# Cortex-M35P register map
Vendor: ARM Ltd.
CPU: Cortex-M35P r0p0, little endian, MPU, FPU, double-precision FPU, VTOR, vendor SysTick, 8 interrupt priority bits
Registers are 32-bit, read-write, no defined reset value unless marked. A register's access mark holds for its fields unless they carry their own. Offsets are from the block's base; [hi:lo] are bit positions; {n}, {i} and the like mark numbered series.

## CM — Cache Maintenance Operations
Base ?
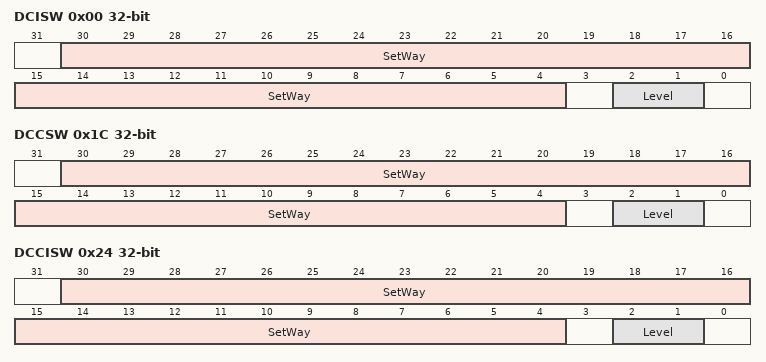
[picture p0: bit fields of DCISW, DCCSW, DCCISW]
0x00 DCISW wo
  [30:4] SetWay — Cache set/way
  [2:1] Level — Cache level
0x00 ICIALLU wo
  [30:0] Ignored — The value written to this field is ignored
0x08 ICIMVAU wo
  [30:0] ADDRESS
0x0C DCIMVAC wo
  [30:0] ADDRESS
0x14 DCCMVAU wo
  [30:0] ADDRESS
0x18 DCCMVAC wo
  [30:0] ADDRESS
0x1C DCCSW wo
  [30:4] SetWay — Cache set/way
  [2:1] Level — Cache level
0x20 DCCIMVAC wo
  [30:0] ADDRESS
0x24 DCCISW wo
  [30:4] SetWay — Cache set/way
  [2:1] Level — Cache level
0x28 BPIALL wo
  [30:0] Ignored

## ICB — Interrupt Control Registers
Base ?
0x00 ICTR ro
  [2:0] INTLINESNUM — Interrupt line set number
0x04 ACTLR
0x08 CPPWR
  [23] SUS11 — State UNKNOWN Secure only 11
  [22] SU11 — State UNKNOWN 11
  [21] SUS10 — State UNKNOWN Secure only 10
  [20] SU10 — State UNKNOWN 10
  [n] SUS{n} (n=0..7) — State UNKNOWN Secure only {n}
  [n] SU{n} (n=0..7) — State UNKNOWN {n}

## DCB — Debug Registers
Base ?
0x00 DHCSR
  [26] S_RESTART_ST — Restart sticky status
  [25] S_RESET_ST — Reset sticky status
  [24] S_RETIRE_ST — Retire sticky status
  [20] S_SDE — Secure debug enabled
  [19] S_LOCKUP — Lockup status
  [18] S_SLEEP — Sleeping status
  [17] S_HALT — Halted status
  [30:16] DBGKEY — Debug key
  [16] S_REGRDY — Register ready status
  [5] C_SNAPSTALL — Snap stall control
  [3] C_MASKINTS — Mask interrupts control
  [2] C_STEP — Step control
  [1] C_HALT — Halt control
  [0] C_DEBUGEN — Debug enable control
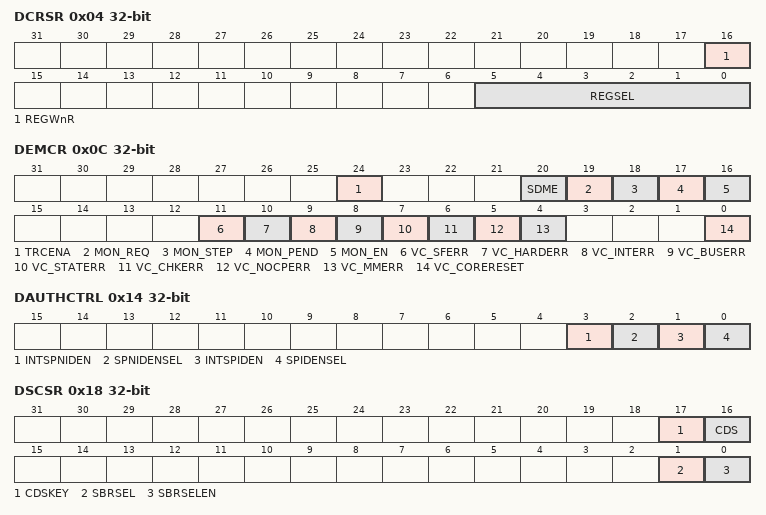
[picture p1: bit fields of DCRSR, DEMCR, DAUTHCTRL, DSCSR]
0x04 DCRSR wo
  [16] REGWnR — Register write/not-read
  [5:0] REGSEL — Register selector
0x08 DCRDR
  [30:0] DBGTMP — Data temporary buffer
0x0C DEMCR ro
  [24] TRCENA — Trace enable
  [20] SDME — Secure DebugMonitor enable
  [19] MON_REQ — Monitor request
  [18] MON_STEP — Monitor step
  [17] MON_PEND — Monitor pend
  [16] MON_EN — Monitor enable
  [11] VC_SFERR — Vector Catch SecureFault
  [10] VC_HARDERR — Vector Catch HardFault errors
  [9] VC_INTERR — Vector Catch interrupt errors
  [8] VC_BUSERR — Vector Catch BusFault errors
  [7] VC_STATERR — Vector Catch state errors
  [6] VC_CHKERR — Vector Catch check errors
  [5] VC_NOCPERR — Vector Catch NOCP errors
  [4] VC_MMERR — Vector Catch MemManage errors
  [0] VC_CORERESET — Vector Catch core reset
0x14 DAUTHCTRL
  [3] INTSPNIDEN — Internal Secure non-invasive debug enable
  [2] SPNIDENSEL — Secure non-invasive debug enable select
  [1] INTSPIDEN — Internal Secure invasive debug enable
  [0] SPIDENSEL — Secure invasive debug enable select
0x18 DSCSR ro
  [17] CDSKEY — CDS write-enable key
  [16] CDS — Current domain Secure
  [1] SBRSEL — Secure Banked register select
  [0] SBRSELEN — Secure Banked register select enable

## DIB — Identification Registers
Base ?
0x00 DLAR wo
  [30:0] KEY — Lock Access control
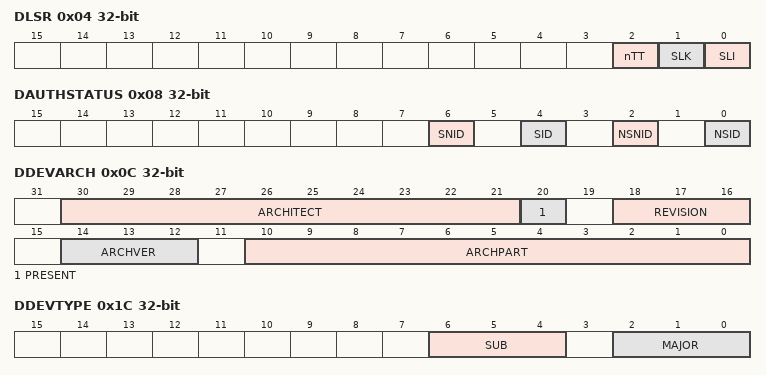
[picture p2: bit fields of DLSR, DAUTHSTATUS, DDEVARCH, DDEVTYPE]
0x04 DLSR ro
  [2] nTT — Not thirty-two bit
  [1] SLK — Software Lock status
  [0] SLI — Software Lock implemented
0x08 DAUTHSTATUS ro
  [6] SNID — Secure Non-invasive Debug
  [4] SID — Secure Invasive Debug
  [2] NSNID — Non-secure Non-invasive Debug
  [0] NSID — Non-secure Invasive Debug
0x0C DDEVARCH ro
  [30:21] ARCHITECT
  [20] PRESENT — DEVARCH Present
  [18:16] REVISION
  [14:12] ARCHVER — Architecture Version
  [10:0] ARCHPART — Architecture Part
0x1C DDEVTYPE ro
  [6:4] SUB — Sub-type
  [2:0] MAJOR — Major type
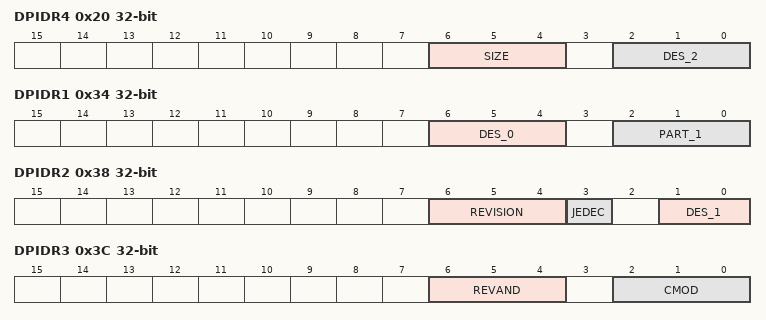
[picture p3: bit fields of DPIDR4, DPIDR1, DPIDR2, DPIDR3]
0x20 DPIDR4 ro
  [6:4] SIZE — 4KB count
  [2:0] DES_2 — JEP106 continuation code
{0x10+4i} DPIDR{i} ro (i=5..7)
0x30 DPIDR0 ro
  [6:0] PART_0 — Part number bits [7:0]
0x34 DPIDR1 ro
  [6:4] DES_0 — JEP106 identification code bits [3:0]
  [2:0] PART_1 — Part number bits [11:8]
0x38 DPIDR2 ro
  [6:4] REVISION — Component revision
  [3] JEDEC — JEDEC assignee value is used
  [1:0] DES_1 — JEP106 identification code bits [6:4]
0x3C DPIDR3 ro
  [6:4] REVAND
  [2:0] CMOD — Customer Modified
0x40 DCIDR0 ro
  [6:0] PRMBL_0 — CoreSight component identification preamble
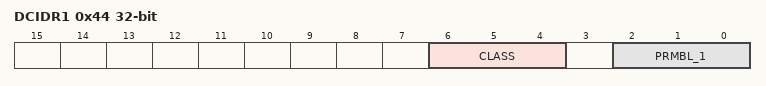
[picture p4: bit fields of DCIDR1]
0x44 DCIDR1 ro
  [6:4] CLASS — CoreSight component class
  [2:0] PRMBL_1 — CoreSight component identification preamble
0x48 DCIDR2 ro
  [6:0] PRMBL_2 — CoreSight component identification preamble
0x4C DCIDR3 ro
  [6:0] PRMBL_3 — CoreSight component identification preamble
